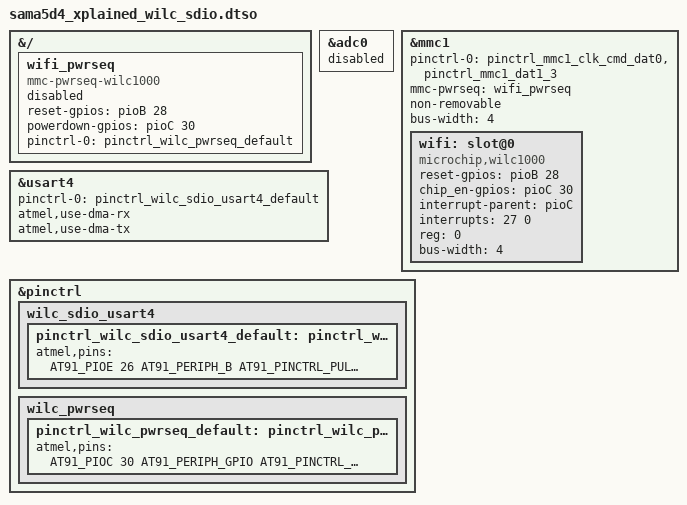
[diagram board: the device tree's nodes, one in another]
// SPDX-License-Identifier: (GPL-2.0+ OR MIT)
/*
 * Device Tree file for SAMA5D4 Xplained
 * board overlay blob for WILC SDIO devices.
 *
 * Copyright (C) 2020 Microchip Technology, Inc.
 * Author: Claudiu Beznea <claudiu.beznea@microchip.com>
 *
 */
/dts-v1/;
/plugin/;

#include "dt-bindings/pinctrl/at91.h"
#include <dt-bindings/gpio/gpio.h>

&{/} {
	wifi_pwrseq: wifi_pwrseq {
		compatible = "mmc-pwrseq-wilc1000", "mmc-pwrseq-wilc";
		reset-gpios = <&pioB 28 GPIO_ACTIVE_HIGH>;
		powerdown-gpios = <&pioC 30 GPIO_ACTIVE_HIGH>;
		pinctrl-0 = <&pinctrl_wilc_pwrseq_default>;
		pinctrl-names = "default";
		status = "disabled";
	};
};

&adc0 {
	status = "disabled"; /* conflict on PC30. */
};

&mmc1 {
	#address-cells = <1>;
	#size-cells = <0>;
	pinctrl-names = "default";
	pinctrl-0 = <&pinctrl_mmc1_clk_cmd_dat0 &pinctrl_mmc1_dat1_3>;
	mmc-pwrseq = <&wifi_pwrseq>;
	non-removable;
	bus-width = <4>;
	status = "okay";

	wifi: slot@0 {
		compatible = "microchip,wilc1000", "microchip,wilc3000", "atmel,wilc_sdio";
		reset-gpios = <&pioB 28 GPIO_ACTIVE_HIGH>;
		chip_en-gpios = <&pioC 30 GPIO_ACTIVE_HIGH>;
		interrupt-parent = <&pioC>;
		interrupts = <27 0>;
		reg = <0>;
		bus-width = <4>;
		status = "okay";
	};
};

&usart4 {
	pinctrl-names = "default";
	pinctrl-0 = <&pinctrl_wilc_sdio_usart4_default>;
	atmel,use-dma-rx;
	atmel,use-dma-tx;
	status = "okay";
};

&pinctrl {
	wilc_sdio_usart4 {
		pinctrl_wilc_sdio_usart4_default: pinctrl_wilc_sdio_usart4 {
			atmel,pins = <AT91_PIOE 26 AT91_PERIPH_B AT91_PINCTRL_PULL_UP	/* RXD */
				      AT91_PIOE 27 AT91_PERIPH_B AT91_PINCTRL_NONE	/* TXD */
				      AT91_PIOE 28 AT91_PERIPH_B AT91_PINCTRL_NONE	/* RTS */
				      AT91_PIOE 0 AT91_PERIPH_C AT91_PINCTRL_NONE>;	/* CTS */
		};
	};

	wilc_pwrseq {
		pinctrl_wilc_pwrseq_default: pinctrl_wilc_pwrseq {
			atmel,pins = <AT91_PIOC 30 AT91_PERIPH_GPIO AT91_PINCTRL_PULL_DOWN
				      AT91_PIOB 28 AT91_PERIPH_GPIO AT91_PINCTRL_PULL_DOWN>;
		};
	};
};
